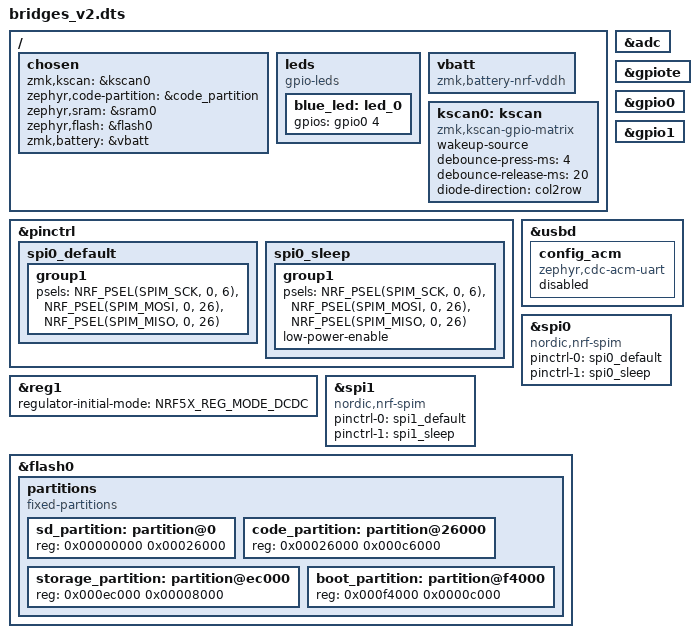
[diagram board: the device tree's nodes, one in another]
/*
 * Copyright (c) 2026 Vincent Franco
 * SPDX-License-Identifier: MIT
 */

/dts-v1/;
#include <nordic/nrf52840_qiaa.dtsi>
#include <common/nordic/nrf52840_uf2_boot_mode.dtsi>

#include "bridges_v2_pinctrl.dtsi"
#include "bridges_v2_common.dtsi"

/ {
    chosen {
      zmk,kscan = &kscan0;
      zephyr,code-partition = &code_partition;
      zephyr,sram = &sram0;
      zephyr,flash = &flash0;
      zmk,battery = &vbatt;
    };

    leds {
        compatible = "gpio-leds";
        blue_led: led_0 {
            gpios = <&gpio0 4 GPIO_ACTIVE_HIGH>;
        };
    };

    vbatt: vbatt {
      compatible = "zmk,battery-nrf-vddh";
    };

    kscan0: kscan {
      compatible = "zmk,kscan-gpio-matrix";
      wakeup-source;

      debounce-press-ms = <4>;
      debounce-release-ms = <20>;
      diode-direction = "col2row";
    };
};

&pinctrl {
    spi0_default: spi0_default {
        group1 {
            psels 
              = <NRF_PSEL(SPIM_SCK, 0, 6)>
              , <NRF_PSEL(SPIM_MOSI, 0, 26)>
              , <NRF_PSEL(SPIM_MISO, 0, 26)>
              ;
        };
    };

    spi0_sleep: spi0_sleep {
        group1 {
            psels 
              = <NRF_PSEL(SPIM_SCK, 0, 6)>
              , <NRF_PSEL(SPIM_MOSI, 0, 26)>
              , <NRF_PSEL(SPIM_MISO, 0, 26)>
              ;
            low-power-enable;
        };
    };
};

&reg1 {
  regulator-initial-mode = <NRF5X_REG_MODE_DCDC>;
};

&adc {
	status = "okay";
};

&gpiote {
    status = "okay";
};

&gpio0 {
	status = "okay";
};

&gpio1 {
	status = "okay";
};

&usbd {
	status = "okay";
};

&spi0 {
  status = "okay";
  compatible = "nordic,nrf-spim";
  pinctrl-0 = <&spi0_default>;
  pinctrl-1 = <&spi0_sleep>;
  pinctrl-names = "default", "sleep";
};

&spi1 {
    compatible = "nordic,nrf-spim";
    pinctrl-0 = <&spi1_default>;
    pinctrl-1 = <&spi1_sleep>;
    pinctrl-names = "default", "sleep";
};

zephyr_udc0: &usbd {
    status = "okay";

    /* USB serial port for host tools such as the pointing tuner. Only a
     * central uses it; the bridges_v2_central snippet enables it. */
    config_acm: config_acm {
        compatible = "zephyr,cdc-acm-uart";
        status = "disabled";
    };
};

&flash0 {
	/*
	 * For more information, see:
	 * http://docs.zephyrproject.org/latest/devices/dts/flash_partitions.html
	 */
  partitions {
    compatible = "fixed-partitions";
    #address-cells = <1>;
		#size-cells = <1>;

    sd_partition: partition@0 {
      reg = <0x00000000 0x00026000>;
    };
    code_partition: partition@26000 {
      reg = <0x00026000 0x000c6000>;
    };

    /*
     * The flash starting at 0x000ec000 and ending at
     * 0x000f3fff is reserved for use by the application.
     */

    /*
     * Storage partition will be used by FCB/LittleFS/NVS
     * if enabled.
     */
		storage_partition: partition@ec000 {
			reg = <0x000ec000 0x00008000>;
		};

		boot_partition: partition@f4000 {
			reg = <0x000f4000 0x0000c000>;
		};
  };
};
